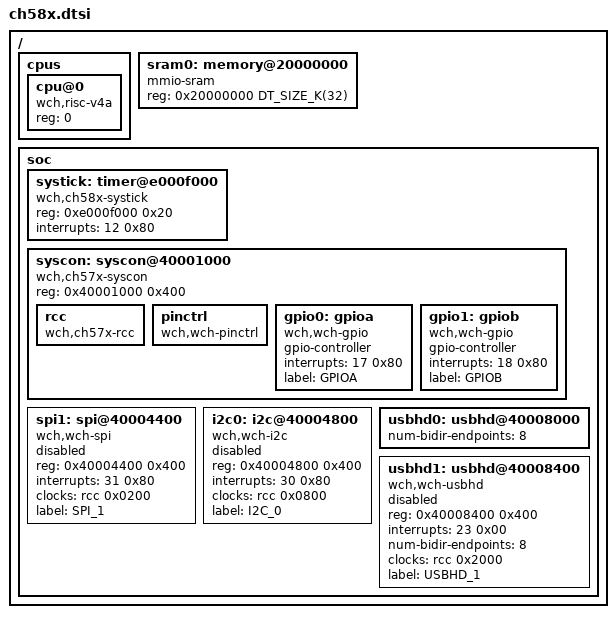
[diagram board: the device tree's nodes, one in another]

#include <wch/ch57x/ch57x_58x.dtsi>
#include <mem.h>

/ {
	cpus {
		#address-cells = <1>;
		#size-cells = <0>;

		cpu@0 {
			device_type = "cpu";
			compatible = "wch,risc-v4a";
			reg = <0>;
		};
	};

	sram0: memory@20000000 {
		compatible = "mmio-sram";
		reg = <0x20000000 DT_SIZE_K(32)>;
	};

	soc {
		systick: timer@e000f000 {
			compatible = "wch,ch58x-systick";
			reg = <0xe000f000 0x20>;
			interrupts = <12 0x80>;
		};

		syscon: syscon@40001000 {
			compatible = "wch,ch57x-syscon";
			reg = <0x40001000 0x400>;

			rcc: rcc {
				#clock-cells = <1>;
				compatible = "wch,ch57x-rcc";
			};

			pinctrl: pinctrl {
				compatible = "wch,wch-pinctrl";
			};

			gpio0: gpioa {
				compatible = "wch,wch-gpio";
				gpio-controller;
				#gpio-cells = <2>;
				interrupts = <17 0x80>;
				//pin-mask = <0x00ff30>;
				label = "GPIOA";
			};

			gpio1: gpiob {
				compatible = "wch,wch-gpio";
				gpio-controller;
				#gpio-cells = <2>;
				interrupts = <18 0x80>;
				//pin-mask = <0xc0fcd1>;
				label = "GPIOB";
			};
		};

		spi1: spi@40004400 {
			compatible = "wch,wch-spi";
			reg = <0x40004400 0x400>;
			interrupts = <31 0x80>;	/* share with pwm */
			clocks = <&rcc 0x0200>;
			label = "SPI_1";
			status = "disabled";
		};

		i2c0: i2c@40004800 {
			compatible = "wch,wch-i2c";
			reg = <0x40004800 0x400>;
			interrupts = <30 0x80>;
			clocks = <&rcc 0x0800>;
			label = "I2C_0";
			status = "disabled";
		};

		usbhd0: usbhd@40008000 {
			num-bidir-endpoints = <8>;
		};

		usbhd1: usbhd@40008400 {
			compatible = "wch,wch-usbhd";
			reg = <0x40008400 0x400>;
			interrupts = <23 0x00>;
			num-bidir-endpoints = <8>;
			clocks = <&rcc 0x2000>;
			label = "USBHD_1";
			status = "disabled";
		};


	};


};



